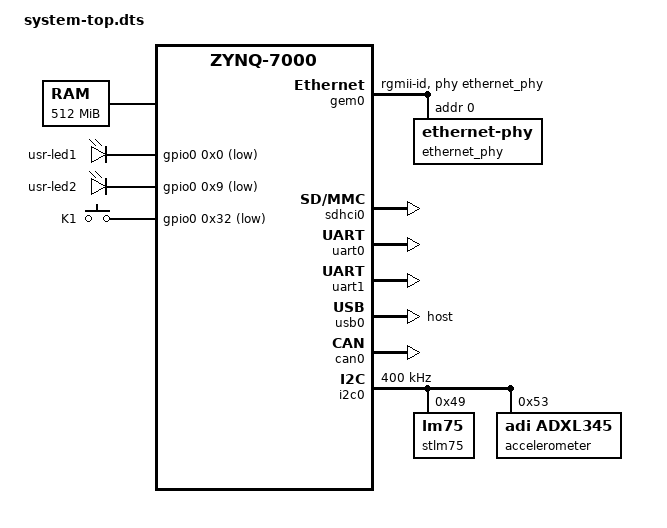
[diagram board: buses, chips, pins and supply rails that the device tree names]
/*
 * CAUTION: This file is automatically generated by Xilinx.
 * Version: HSI 2018.3.1
 * Today is: Sun May 12 16:37:27 2019
 */


/dts-v1/;
#include "zynq-7000.dtsi"
#include "pl.dtsi"
#include "pcw.dtsi"
/ {
	chosen {
		bootargs = "earlycon drm.debug=0xff";
		stdout-path = "serial0:115200n8";
	};
	aliases {
		ethernet0 = &gem0;
		i2c0 = &i2c0;
		serial0 = &uart1;
		spi0 = &qspi;
	};
	memory {
		device_type = "memory";
		reg = <0x0 0x20000000>;
	};
	cpus {
		/delete-node/ cpu@1 ;
	};
    gpio-leds {
		compatible = "gpio-leds";
		usr-led1 {
			label = "usr-led1";
			gpios = <&gpio0 0x0 0x1>;
			default-state = "off";
		};

		usr-led2 {
			label = "usr-led2";
			gpios = <&gpio0 0x9 0x1>;
			default-state = "off";
		};
	};

	gpio-keys {
		compatible = "gpio-keys";
		autorepeat;
		K1 {
			label = "K1";
			gpios = <&gpio0 0x32 0x1>;
			linux,code = <0x66>;
			gpio-key,wakeup;
			autorepeat;
		};
	};
};

&gem0 {
	status = "okay";
	phy-mode = "rgmii-id";
	phy-handle = <&ethernet_phy>;

	ethernet_phy: ethernet-phy@0 {
		reg = <0x0>;
	};
};

&sdhci0 {
	status = "okay";
};

&uart0 {
	status = "okay";
};

&uart1 {
	status = "okay";
};

&usb0 {
	status = "okay";
	dr_mode = "host";
};

&can0 {
	status = "okay";
};

&i2c0 {
	status = "okay";
	clock-frequency = <400000>;

	stlm75@49 {
		status = "okay";
		compatible = "lm75";
		reg = <0x49>;
	};

	accelerometer@53 {
		compatible = "adi,adxl345", "adxl345", "adi,adxl34x", "adxl34x";
		reg = <0x53>;
		interrupt-parent = <&intc>;
		interrupts = <0x0 0x1e 0x4>;
	};
};
